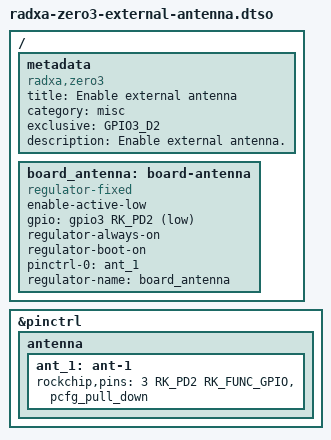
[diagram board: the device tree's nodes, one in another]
/dts-v1/;
/plugin/;

#include <dt-bindings/gpio/gpio.h>
#include <dt-bindings/pinctrl/rockchip.h>


/ {
	metadata {
		title = "Enable external antenna";
		compatible = "radxa,zero3";
		category = "misc";
		exclusive = "GPIO3_D2";
		description = "Enable external antenna.";
	};

	fragment@0 {
		target-path = "/";

		__overlay__ {
			board_antenna: board-antenna {
				status = "okay";
				compatible = "regulator-fixed";
				enable-active-low;
				gpio = <&gpio3 RK_PD2 GPIO_ACTIVE_LOW>;
				regulator-always-on;
				regulator-boot-on;
				pinctrl-0 = <&ant_1>;
				pinctrl-names = "default";
				regulator-name = "board_antenna";
			};
		};
	};

	fragment@1 {
		target = <&pinctrl>;

		__overlay__ {
			antenna {
				ant_1: ant-1 {
					rockchip,pins = <3 RK_PD2 RK_FUNC_GPIO &pcfg_pull_down>;
				};
			};
		};
	};
};
